# CY8C5888LTI_LP097 register map
File version: 0.1
CY8C58LP
Registers are 8-bit, read-write, no defined reset value unless marked. A register's access mark holds for its fields unless they carry their own. Offsets are from the block's base; lines under a group give offsets from that group; [hi:lo] are bit positions; {n}, {i} and the like mark numbered series; 'fields as' and 'values as' point back to an identical list; <NAME> marks a mode.

## Memory map
0x00000000 Motor_PWM
0x00000000 Actuator_PWM
0x00000000 Actuator_Dir
0x00000000 Color_Counter
0x00000000 RPI_UART — UART
0x00000000 Color_PWM
0x00000000 Weight_ADC — SAR ADC
0x00000000 Color_Reset

## Motor_PWM
Base 0x00000000
0x4000642A Motor_PWM_COMPARE_Reg_ — UDB.D0 - Assigned Compare Value
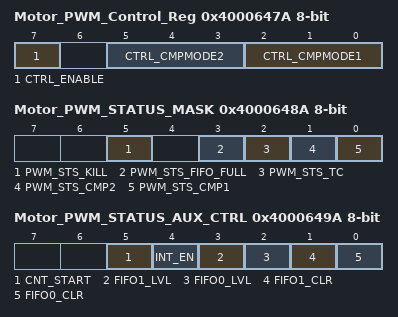
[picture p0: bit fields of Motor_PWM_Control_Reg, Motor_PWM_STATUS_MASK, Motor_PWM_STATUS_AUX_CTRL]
0x4000647A Motor_PWM_Control_Reg — UDB Control Register - Assigned Control Register Value
  [7] CTRL_ENABLE — Enable the PWM
  [5:3] CTRL_CMPMODE2 — Compare mode 2
  [2:0] CTRL_CMPMODE1 — Compare mode 1
0x4000648A Motor_PWM_STATUS_MASK — UDB Status bits Interrupt Mask Enable Register
  [5] PWM_STS_KILL ro — Enables the Interrupt on Kill
  [3] PWM_STS_FIFO_FULL ro — FIFO Full Status Mask
  [2] PWM_STS_TC ro — Enables the Interrupt on Terminal Count
  [1] PWM_STS_CMP2 ro — Enables the Interrupt on Compare 2
  [0] PWM_STS_CMP1 ro — Enables the Interrupt on Compare 1
0x4000649A Motor_PWM_STATUS_AUX_CTRL — UDB Auxilliary Control Register
  [5] CNT_START — FIFO0 clear
    0=E_CNT_START0 (Disable counter); 1=E_CNT_START1 (Enable counter)
  [4] INT_EN
    0=E_INT_EN0 (Interrupt disabled); 1=E_INT_EN1 (Interrupt enabled)
  [3] FIFO1_LVL — FIFO level
    0=E_FIFO_LVL_0 (FIFO LVL: input mode: FIFO not full; output mode: FIFO not empty); 1=E_FIFO_LVL_1 (FIFO LVL: input mode: FIFO at least 1/2 empty; output mode: FIFO at least 1/2 full)
  [2] FIFO0_LVL — FIFO level
    values as FIFO1_LVL
  [1] FIFO1_CLR — FIFO1 clear
    0=E_FIFO_CLR_0 (Normal FIFO operation); 1=E_FIFO_CLR_1 (Clear FIFO state)
  [0] FIFO0_CLR — FIFO0 clear
    values as FIFO1_CLR

## Actuator_PWM
Base 0x00000000
0x40006425 Actuator_PWM_COMPARE_Reg_ — UDB.D0 - Assigned Compare Value
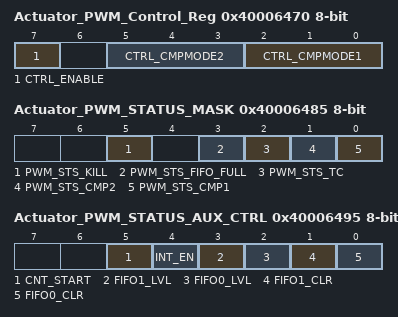
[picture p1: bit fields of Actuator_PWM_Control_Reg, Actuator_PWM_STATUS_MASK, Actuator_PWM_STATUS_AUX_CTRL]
0x40006470 Actuator_PWM_Control_Reg — UDB Control Register - Assigned Control Register Value
  [7] CTRL_ENABLE — Enable the PWM
  [5:3] CTRL_CMPMODE2 — Compare mode 2
  [2:0] CTRL_CMPMODE1 — Compare mode 1
0x40006485 Actuator_PWM_STATUS_MASK — UDB Status bits Interrupt Mask Enable Register
  fields as Motor_PWM.Motor_PWM_STATUS_MASK
0x40006495 Actuator_PWM_STATUS_AUX_CTRL — UDB Auxilliary Control Register
  fields as Motor_PWM.Motor_PWM_STATUS_AUX_CTRL

## Actuator_Dir
Base 0x00000000
0x40006475 Actuator_Dir_CONTROL_REG

## Color_Counter
Base 0x00000000
0x40006400 Color_Counter_COUNTER 16-bit — UDB.A0 - Current Counter Value
0x40006420 Color_Counter_PERIOD 16-bit — UDB.D0 - Assigned Period
0x40006430 Color_Counter_COMPARE 16-bit — UDB.D1 - Assigned Compare Value
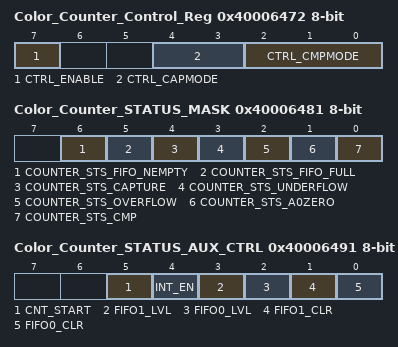
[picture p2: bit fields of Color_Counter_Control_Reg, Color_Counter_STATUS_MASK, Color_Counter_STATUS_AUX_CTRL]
0x40006472 Color_Counter_Control_Reg — UDB Control Register - Assigned Control Register Value
  [7] CTRL_ENABLE — Enable Counter
  [4:3] CTRL_CAPMODE — Capture mode
  [2:0] CTRL_CMPMODE — Compare mode
0x40006481 Color_Counter_STATUS_MASK — UDB Status bits Interrupt Mask Enable Register
  [6] COUNTER_STS_FIFO_NEMPTY — FIFO Not Empty Status
  [5] COUNTER_STS_FIFO_FULL — FIFO Full Status
  [4] COUNTER_STS_CAPTURE — Capture Status
  [3] COUNTER_STS_UNDERFLOW — Underflow status
  [2] COUNTER_STS_OVERFLOW — Overflow status
  [1] COUNTER_STS_A0ZERO — A0 Zero ouput status
  [0] COUNTER_STS_CMP — Compare output status
0x40006491 Color_Counter_STATUS_AUX_CTRL — UDB Auxilliary Control Register
  fields as Motor_PWM.Motor_PWM_STATUS_AUX_CTRL

## RPI_UART — UART
Base 0x00000000
0x40006428 RX_RPI_UART_RX_ADDRESS1 — RX Address1 Register
0x40006438 RX_RPI_UART_RX_ADDRESS2 — RX Address2 Register
0x40006448 RX_RPI_UART_RX_DATA — RX Data Register
0x4000654A TX_RPI_UART_TX_DATA — TX Data Register
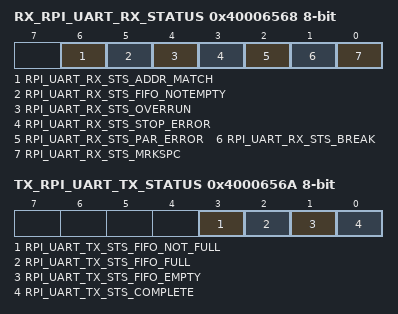
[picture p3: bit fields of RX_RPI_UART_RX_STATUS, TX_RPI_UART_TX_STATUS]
0x40006568 RX_RPI_UART_RX_STATUS — RX status register
  [6] RPI_UART_RX_STS_ADDR_MATCH ro, [5] RPI_UART_RX_STS_FIFO_NOTEMPTY ro, [4] RPI_UART_RX_STS_OVERRUN ro, [3] RPI_UART_RX_STS_STOP_ERROR ro, [2] RPI_UART_RX_STS_PAR_ERROR ro, [1] RPI_UART_RX_STS_BREAK ro, [0] RPI_UART_RX_STS_MRKSPC ro
0x4000656A TX_RPI_UART_TX_STATUS — TX status register
  [3] RPI_UART_TX_STS_FIFO_NOT_FULL ro, [2] RPI_UART_TX_STS_FIFO_FULL ro, [1] RPI_UART_TX_STS_FIFO_EMPTY ro, [0] RPI_UART_TX_STS_COMPLETE ro

## Color_PWM
Base 0x00000000
0x40006422 Color_PWM_COMPARE_Reg 16-bit — UDB.D0 - Assigned Compare Value
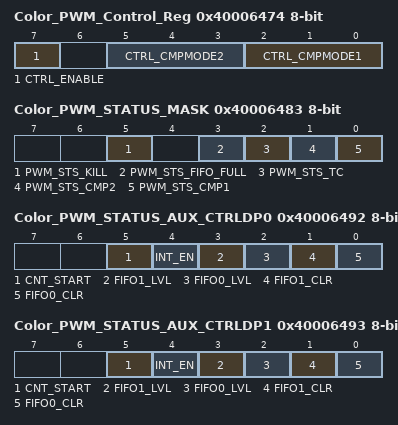
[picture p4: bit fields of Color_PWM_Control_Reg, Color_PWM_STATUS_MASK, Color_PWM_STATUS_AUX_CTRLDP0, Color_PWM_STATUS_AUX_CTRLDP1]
0x40006474 Color_PWM_Control_Reg — UDB Control Register - Assigned Control Register Value
  [7] CTRL_ENABLE — Enable the PWM
  [5:3] CTRL_CMPMODE2 — Compare mode 2
  [2:0] CTRL_CMPMODE1 — Compare mode 1
0x40006483 Color_PWM_STATUS_MASK — UDB Status bits Interrupt Mask Enable Register
  fields as Motor_PWM.Motor_PWM_STATUS_MASK
0x40006492 Color_PWM_STATUS_AUX_CTRLDP0 — UDB Auxilliary Control Register
  fields as Motor_PWM.Motor_PWM_STATUS_AUX_CTRL
0x40006493 Color_PWM_STATUS_AUX_CTRLDP1 — UDB Auxilliary Control Register
  fields as Motor_PWM.Motor_PWM_STATUS_AUX_CTRL

## Weight_ADC — SAR ADC
Base 0x00000000
0x40004614 SAR_TR0 — SAR trim register
{0x40005900+i} SAR_CSR{i} (i=0..6) — SAR status and control register {i}
0x40005B20 SAR_SW0 — SAR Analog Routing Register 0
{0x40005B20+i} SAR_SW{i} (i=2..4) — SAR Analog Routing Register {i}
0x40005B26 SAR_SW6 — SAR Analog Routing Register 6
0x40005B27 SAR_CLK — SAR Clock Selection Register
0x40005BA0 SAR_WRK 16-bit — SAR working register

## Color_Reset
Base 0x00000000
0x40006473 Color_Reset_CONTROL_REG
